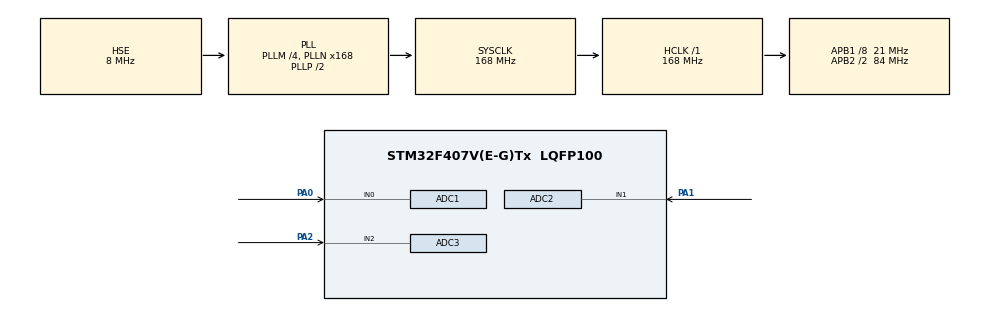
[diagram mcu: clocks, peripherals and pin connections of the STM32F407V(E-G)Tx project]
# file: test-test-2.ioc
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ADC1.Channel-4\#ChannelRegularConversion=ADC_CHANNEL_0
ADC1.NbrOfConversionFlag=1
ADC1.Rank-4\#ChannelRegularConversion=1
ADC1.SamplingTime-4\#ChannelRegularConversion=ADC_SAMPLETIME_3CYCLES
ADC1.master=1
ADC2.Channel-0\#ChannelRegularConversion=ADC_CHANNEL_1
ADC2.NbrOfConversionFlag=1
ADC2.Rank-0\#ChannelRegularConversion=1
ADC2.SamplingTime-0\#ChannelRegularConversion=ADC_SAMPLETIME_3CYCLES
ADC3.Channel-0\#ChannelRegularConversion=ADC_CHANNEL_2
ADC3.NbrOfConversionFlag=1
ADC3.Rank-0\#ChannelRegularConversion=1
ADC3.SamplingTime-0\#ChannelRegularConversion=ADC_SAMPLETIME_3CYCLES
Mcu.Family=STM32F4
Mcu.Name=STM32F407V(E-G)Tx
Mcu.Package=LQFP100
NVIC.PriorityGroup=NVIC_PRIORITYGROUP_4
PA0-WKUP.Signal=ADCx_IN0
PA1.Signal=ADCx_IN1
PA2.Signal=ADCx_IN2
PH0-OSC_IN.Mode=HSE-External-Oscillator
PH0-OSC_IN.Signal=RCC_OSC_IN
PH1-OSC_OUT.Mode=HSE-External-Oscillator
PH1-OSC_OUT.Signal=RCC_OSC_OUT
ProjectManager.HeapSize=0x200
ProjectManager.StackSize=0x400
ProjectManager.TargetToolchain=EWARM
RCC.48MHZClocksFreq_Value=84000000
RCC.AHBFreq_Value=168000000
RCC.APB1CLKDivider=RCC_HCLK_DIV8
RCC.APB1Freq_Value=21000000
RCC.APB1TimFreq_Value=42000000
RCC.APB2CLKDivider=RCC_HCLK_DIV2
RCC.APB2Freq_Value=84000000
RCC.APB2TimFreq_Value=168000000
RCC.CortexFreq_Value=168000000
RCC.HCLKFreq_Value=168000000
RCC.HSE_VALUE=8000000
RCC.HSI_VALUE=16000000
RCC.LSE_VALUE=32768
RCC.PLLM=4
RCC.PLLN=168
RCC.PLLSourceVirtual=RCC_PLLSOURCE_HSE
RCC.SYSCLKFreq_VALUE=168000000
RCC.SYSCLKSource=RCC_SYSCLKSOURCE_PLLCLK
RCC.VCOOutputFreq_Value=336000000
SH.ADCx_IN0.0=ADC1_IN0,IN0
SH.ADCx_IN1.0=ADC2_IN1,IN1
SH.ADCx_IN2.0=ADC3_IN2,IN2
board=test-test-2

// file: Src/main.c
#include "main.h"
#include "stm32f4xx_hal.h"

ADC_HandleTypeDef hadc1;
ADC_HandleTypeDef hadc2;
ADC_HandleTypeDef hadc3;

/* USER CODE BEGIN PV */
/* Private variables ---------------------------------------------------------*/
int res1 =0;
int res2=0;
int res3=0;
/* USER CODE END PV */

void SystemClock_Config(void);
static void MX_GPIO_Init(void);
static void MX_ADC1_Init(void);
static void MX_ADC2_Init(void);
static void MX_ADC3_Init(void);

/* USER CODE BEGIN PFP */
/* Private function prototypes -----------------------------------------------*/

/* USER CODE END PFP */

int main(void)
{

  /* MCU Configuration----------------------------------------------------------*/

  /* Reset of all peripherals, Initializes the Flash interface and the Systick. */
  HAL_Init();

  /* Configure the system clock */
  SystemClock_Config();

  /* Initialize all configured peripherals */
  MX_GPIO_Init();
  MX_ADC1_Init();
  MX_ADC2_Init();
  MX_ADC3_Init();

  /* Infinite loop */
  /* USER CODE BEGIN WHILE */
  while (1)
  {
    HAL_ADC_Start(&hadc1);
    HAL_ADC_Start(&hadc2);
    HAL_ADC_Start(&hadc3);
    HAL_ADC_PollForConversion(&hadc1, HAL_MAX_DELAY);
    HAL_ADC_PollForConversion(&hadc2, HAL_MAX_DELAY);
    HAL_ADC_PollForConversion(&hadc3, HAL_MAX_DELAY);
    res1 = HAL_ADC_GetValue(&hadc1);
    res2 = HAL_ADC_GetValue(&hadc2);
    res3 = HAL_ADC_GetValue(&hadc3);

    printf("1 : %i\n2 : %i\n3 : %i\n\n", res1,res2,res3);
    HAL_Delay(1000);
  /* USER CODE END WHILE */

  /* USER CODE BEGIN 3 */
    HAL_ADC_Stop(&hadc1);
    HAL_ADC_Stop(&hadc2);
    HAL_ADC_Stop(&hadc3);
  }
  /* USER CODE END 3 */

}

void SystemClock_Config(void)
{

  RCC_OscInitTypeDef RCC_OscInitStruct;
  RCC_ClkInitTypeDef RCC_ClkInitStruct;

    /**Configure the main internal regulator output voltage
    */
  __HAL_RCC_PWR_CLK_ENABLE();

  __HAL_PWR_VOLTAGESCALING_CONFIG(PWR_REGULATOR_VOLTAGE_SCALE1);

    /**Initializes the CPU, AHB and APB busses clocks
    */
  RCC_OscInitStruct.OscillatorType = RCC_OSCILLATORTYPE_HSE;
  RCC_OscInitStruct.HSEState = RCC_HSE_ON;
  RCC_OscInitStruct.PLL.PLLState = RCC_PLL_ON;
  RCC_OscInitStruct.PLL.PLLSource = RCC_PLLSOURCE_HSE;
  RCC_OscInitStruct.PLL.PLLM = 4;
  RCC_OscInitStruct.PLL.PLLN = 168;
  RCC_OscInitStruct.PLL.PLLP = RCC_PLLP_DIV2;
  RCC_OscInitStruct.PLL.PLLQ = 4;
  if (HAL_RCC_OscConfig(&RCC_OscInitStruct) != HAL_OK)
  {
    _Error_Handler(__FILE__, __LINE__);
  }

    /**Initializes the CPU, AHB and APB busses clocks
    */
  RCC_ClkInitStruct.ClockType = RCC_CLOCKTYPE_HCLK|RCC_CLOCKTYPE_SYSCLK
                              |RCC_CLOCKTYPE_PCLK1|RCC_CLOCKTYPE_PCLK2;
  RCC_ClkInitStruct.SYSCLKSource = RCC_SYSCLKSOURCE_PLLCLK;
  RCC_ClkInitStruct.AHBCLKDivider = RCC_SYSCLK_DIV1;
  RCC_ClkInitStruct.APB1CLKDivider = RCC_HCLK_DIV8;
  RCC_ClkInitStruct.APB2CLKDivider = RCC_HCLK_DIV2;

  if (HAL_RCC_ClockConfig(&RCC_ClkInitStruct, FLASH_LATENCY_5) != HAL_OK)
  {
    _Error_Handler(__FILE__, __LINE__);
  }

    /**Configure the Systick interrupt time
    */
  HAL_SYSTICK_Config(HAL_RCC_GetHCLKFreq()/1000);

    /**Configure the Systick
    */
  HAL_SYSTICK_CLKSourceConfig(SYSTICK_CLKSOURCE_HCLK);

  /* SysTick_IRQn interrupt configuration */
  HAL_NVIC_SetPriority(SysTick_IRQn, 0, 0);
}

/* ADC1 init function */
static void MX_ADC1_Init(void)
{

  ADC_ChannelConfTypeDef sConfig;

    /**Configure the global features of the ADC (Clock, Resolution, Data Alignment and number of conversion)
    */
  hadc1.Instance = ADC1;
  hadc1.Init.ClockPrescaler = ADC_CLOCK_SYNC_PCLK_DIV4;
  hadc1.Init.Resolution = ADC_RESOLUTION_12B;
  hadc1.Init.ScanConvMode = DISABLE;
  hadc1.Init.ContinuousConvMode = DISABLE;
  hadc1.Init.DiscontinuousConvMode = DISABLE;
  hadc1.Init.ExternalTrigConvEdge = ADC_EXTERNALTRIGCONVEDGE_NONE;
  hadc1.Init.ExternalTrigConv = ADC_SOFTWARE_START;
  hadc1.Init.DataAlign = ADC_DATAALIGN_RIGHT;
  hadc1.Init.NbrOfConversion = 1;
  hadc1.Init.DMAContinuousRequests = DISABLE;
  hadc1.Init.EOCSelection = ADC_EOC_SINGLE_CONV;
  if (HAL_ADC_Init(&hadc1) != HAL_OK)
  {
    _Error_Handler(__FILE__, __LINE__);
  }

    /**Configure for the selected ADC regular channel its corresponding rank in the sequencer and its sample time.
    */
  sConfig.Channel = ADC_CHANNEL_0;
  sConfig.Rank = 1;
  sConfig.SamplingTime = ADC_SAMPLETIME_3CYCLES;
  if (HAL_ADC_ConfigChannel(&hadc1, &sConfig) != HAL_OK)
  {
    _Error_Handler(__FILE__, __LINE__);
  }

}

/* ADC2 init function */
static void MX_ADC2_Init(void)
{

  ADC_ChannelConfTypeDef sConfig;

    /**Configure the global features of the ADC (Clock, Resolution, Data Alignment and number of conversion)
    */
  hadc2.Instance = ADC2;
  hadc2.Init.ClockPrescaler = ADC_CLOCK_SYNC_PCLK_DIV4;
  hadc2.Init.Resolution = ADC_RESOLUTION_12B;
  hadc2.Init.ScanConvMode = DISABLE;
  hadc2.Init.ContinuousConvMode = DISABLE;
  hadc2.Init.DiscontinuousConvMode = DISABLE;
  hadc2.Init.ExternalTrigConvEdge = ADC_EXTERNALTRIGCONVEDGE_NONE;
  hadc2.Init.ExternalTrigConv = ADC_SOFTWARE_START;
  hadc2.Init.DataAlign = ADC_DATAALIGN_RIGHT;
  hadc2.Init.NbrOfConversion = 1;
  hadc2.Init.DMAContinuousRequests = DISABLE;
  hadc2.Init.EOCSelection = ADC_EOC_SINGLE_CONV;
  if (HAL_ADC_Init(&hadc2) != HAL_OK)
  {
    _Error_Handler(__FILE__, __LINE__);
  }

    /**Configure for the selected ADC regular channel its corresponding rank in the sequencer and its sample time.
    */
  sConfig.Channel = ADC_CHANNEL_1;
  sConfig.Rank = 1;
  sConfig.SamplingTime = ADC_SAMPLETIME_3CYCLES;
  if (HAL_ADC_ConfigChannel(&hadc2, &sConfig) != HAL_OK)
  {
    _Error_Handler(__FILE__, __LINE__);
  }

}

/* ADC3 init function */
static void MX_ADC3_Init(void)
{

  ADC_ChannelConfTypeDef sConfig;

    /**Configure the global features of the ADC (Clock, Resolution, Data Alignment and number of conversion)
    */
  hadc3.Instance = ADC3;
  hadc3.Init.ClockPrescaler = ADC_CLOCK_SYNC_PCLK_DIV4;
  hadc3.Init.Resolution = ADC_RESOLUTION_12B;
  hadc3.Init.ScanConvMode = DISABLE;
  hadc3.Init.ContinuousConvMode = DISABLE;
  hadc3.Init.DiscontinuousConvMode = DISABLE;
  hadc3.Init.ExternalTrigConvEdge = ADC_EXTERNALTRIGCONVEDGE_NONE;
  hadc3.Init.ExternalTrigConv = ADC_SOFTWARE_START;
  hadc3.Init.DataAlign = ADC_DATAALIGN_RIGHT;
  hadc3.Init.NbrOfConversion = 1;
  hadc3.Init.DMAContinuousRequests = DISABLE;
  hadc3.Init.EOCSelection = ADC_EOC_SINGLE_CONV;
  if (HAL_ADC_Init(&hadc3) != HAL_OK)
  {
    _Error_Handler(__FILE__, __LINE__);
  }

    /**Configure for the selected ADC regular channel its corresponding rank in the sequencer and its sample time.
    */
  sConfig.Channel = ADC_CHANNEL_2;
  sConfig.Rank = 1;
  sConfig.SamplingTime = ADC_SAMPLETIME_3CYCLES;
  if (HAL_ADC_ConfigChannel(&hadc3, &sConfig) != HAL_OK)
  {
    _Error_Handler(__FILE__, __LINE__);
  }

}

/** Configure pins as
        * Analog
        * Input
        * Output
        * EVENT_OUT
        * EXTI
*/
static void MX_GPIO_Init(void)
{

  /* GPIO Ports Clock Enable */
  __HAL_RCC_GPIOH_CLK_ENABLE();
  __HAL_RCC_GPIOA_CLK_ENABLE();

}

void _Error_Handler(char *file, int line)
{
  while(1)
  {
  }
}

/************************ (C) COPYRIGHT STMicroelectronics *****END OF FILE****/
